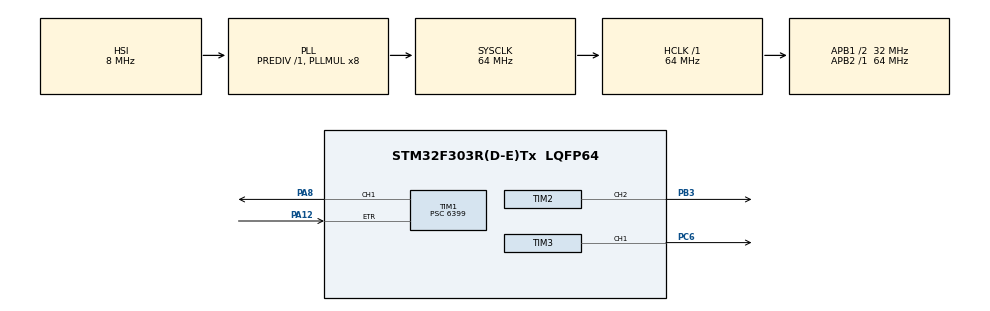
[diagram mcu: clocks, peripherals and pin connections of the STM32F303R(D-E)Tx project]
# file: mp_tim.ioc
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Mcu.Family=STM32F3
Mcu.Name=STM32F303R(D-E)Tx
Mcu.Package=LQFP64
NVIC.PriorityGroup=NVIC_PRIORITYGROUP_4
PA12.Signal=S_TIM1_ETR
PA13.Mode=Serial_Wire
PA13.Signal=SYS_JTMS-SWDIO
PA14.Mode=Serial_Wire
PA14.Signal=SYS_JTCK-SWCLK
PA8.Signal=S_TIM1_CH1
PB3.Signal=S_TIM2_CH2
PC6.Signal=S_TIM3_CH1
ProjectManager.HeapSize=0x200
ProjectManager.StackSize=0x400
ProjectManager.TargetToolchain=STM32CubeIDE
RCC.AHBFreq_Value=64000000
RCC.APB1CLKDivider=RCC_HCLK_DIV2
RCC.APB1Freq_Value=32000000
RCC.APB1TimFreq_Value=64000000
RCC.APB2Freq_Value=64000000
RCC.APB2TimFreq_Value=64000000
RCC.CortexFreq_Value=64000000
RCC.HCLKFreq_Value=64000000
RCC.HSE_VALUE=8000000
RCC.HSI_VALUE=8000000
RCC.LSE_VALUE=32768
RCC.PLLMUL=RCC_PLL_MUL8
RCC.SYSCLKFreq_VALUE=64000000
RCC.SYSCLKSourceVirtual=RCC_SYSCLKSOURCE_PLLCLK
RCC.USBFreq_Value=64000000
SH.S_TIM1_CH1.0=TIM1_CH1,PWM Generation1 CH1
SH.S_TIM1_ETR.0=TIM1_ETR,TriggerSource_ETR
SH.S_TIM2_CH2.0=TIM2_CH2,PWM Generation2 CH2
SH.S_TIM3_CH1.0=TIM3_CH1,PWM Generation1 CH1
TIM1.Channel-PWM\ Generation1\ CH1=TIM_CHANNEL_1
TIM1.OCMode_PWM-PWM\ Generation1\ CH1=TIM_OCMODE_PWM2
TIM1.Period=9999
TIM1.Prescaler=6399
TIM1.Pulse-PWM\ Generation1\ CH1=4999
TIM1.RepetitionCounter=2
TIM1.Slave_TriggerPolarity=TIM_TRIGGERPOLARITY_INVERTED
TIM1.TIM_MasterOutputTrigger=TIM_TRGO_UPDATE
TIM1.TIM_MasterSlaveMode=TIM_MASTERSLAVEMODE_ENABLE
TIM2.Channel-PWM\ Generation2\ CH2=TIM_CHANNEL_2
TIM2.OCMode_PWM-PWM\ Generation2\ CH2=TIM_OCMODE_PWM2
TIM2.Period=9999
TIM2.Prescaler=6399
TIM2.Pulse-PWM\ Generation2\ CH2=4999
TIM2.TIM_MasterOutputTrigger=TIM_TRGO_UPDATE
TIM2.TIM_MasterSlaveMode=TIM_MASTERSLAVEMODE_ENABLE
TIM3.Channel-PWM\ Generation1\ CH1=TIM_CHANNEL_1
TIM3.OCMode_PWM-PWM\ Generation1\ CH1=TIM_OCMODE_PWM2
TIM3.Period=9999
TIM3.Prescaler=6399
TIM3.Pulse-PWM\ Generation1\ CH1=4999
VP_TIM1_VS_ClockSourceINT.Mode=Internal
VP_TIM1_VS_ControllerModeTrigger.Mode=Trigger Mode
VP_TIM1_VS_OPM.Mode=OPM_bit
VP_TIM2_VS_ClockSourceINT.Mode=Internal
VP_TIM2_VS_ClockSourceITR.Mode=TriggerSource_ITR0
VP_TIM2_VS_ControllerModeTrigger.Mode=Trigger Mode
VP_TIM2_VS_OPM.Mode=OPM_bit
VP_TIM3_VS_ClockSourceINT.Mode=Internal
VP_TIM3_VS_ClockSourceITR.Mode=TriggerSource_ITR1
VP_TIM3_VS_ControllerModeTrigger.Mode=Trigger Mode
VP_TIM3_VS_OPM.Mode=OPM_bit
board=custom

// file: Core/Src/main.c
/* USER CODE BEGIN Header */
/**
  ******************************************************************************
  * @file           : main.c
  * @brief          : Main program body
  ******************************************************************************
  * @attention
  *
  * <h2><center>&copy; Copyright (c) 2021 STMicroelectronics.
  * All rights reserved.</center></h2>
  *
  * This software component is licensed by ST under BSD 3-Clause license,
  * the "License"; You may not use this file except in compliance with the
  * License. You may obtain a copy of the License at:
  *                        opensource.org/licenses/BSD-3-Clause
  *
  ******************************************************************************
  */
/* USER CODE END Header */

#include "main.h"

TIM_HandleTypeDef htim1;
TIM_HandleTypeDef htim2;
TIM_HandleTypeDef htim3;

void SystemClock_Config(void);
static void MX_GPIO_Init(void);
static void MX_TIM1_Init(void);
static void MX_TIM2_Init(void);
static void MX_TIM3_Init(void);

int main(void)
{

  /* MCU Configuration--------------------------------------------------------*/

  /* Reset of all peripherals, Initializes the Flash interface and the Systick. */
  HAL_Init();

  /* Configure the system clock */
  SystemClock_Config();

  /* Initialize all configured peripherals */
  MX_GPIO_Init();
  MX_TIM1_Init();
  MX_TIM2_Init();
  MX_TIM3_Init();
  /* USER CODE BEGIN 2 */
  HAL_TIM_OnePulse_Start(&htim1, TIM_CHANNEL_1);
  HAL_TIM_OnePulse_Start(&htim2, TIM_CHANNEL_2);
  HAL_TIM_OnePulse_Start(&htim3, TIM_CHANNEL_1);
  /* USER CODE END 2 */

  /* Infinite loop */
  while (1)
  {

  }
}

void SystemClock_Config(void)
{
  RCC_OscInitTypeDef RCC_OscInitStruct = {0};
  RCC_ClkInitTypeDef RCC_ClkInitStruct = {0};
  RCC_PeriphCLKInitTypeDef PeriphClkInit = {0};

  /** Initializes the CPU, AHB and APB busses clocks
  */
  RCC_OscInitStruct.OscillatorType = RCC_OSCILLATORTYPE_HSI;
  RCC_OscInitStruct.HSIState = RCC_HSI_ON;
  RCC_OscInitStruct.HSICalibrationValue = RCC_HSICALIBRATION_DEFAULT;
  RCC_OscInitStruct.PLL.PLLState = RCC_PLL_ON;
  RCC_OscInitStruct.PLL.PLLSource = RCC_PLLSOURCE_HSI;
  RCC_OscInitStruct.PLL.PLLMUL = RCC_PLL_MUL8;
  RCC_OscInitStruct.PLL.PREDIV = RCC_PREDIV_DIV1;
  if (HAL_RCC_OscConfig(&RCC_OscInitStruct) != HAL_OK)
  {
    Error_Handler();
  }
  /** Initializes the CPU, AHB and APB busses clocks
  */
  RCC_ClkInitStruct.ClockType = RCC_CLOCKTYPE_HCLK|RCC_CLOCKTYPE_SYSCLK
                              |RCC_CLOCKTYPE_PCLK1|RCC_CLOCKTYPE_PCLK2;
  RCC_ClkInitStruct.SYSCLKSource = RCC_SYSCLKSOURCE_PLLCLK;
  RCC_ClkInitStruct.AHBCLKDivider = RCC_SYSCLK_DIV1;
  RCC_ClkInitStruct.APB1CLKDivider = RCC_HCLK_DIV2;
  RCC_ClkInitStruct.APB2CLKDivider = RCC_HCLK_DIV1;

  if (HAL_RCC_ClockConfig(&RCC_ClkInitStruct, FLASH_LATENCY_2) != HAL_OK)
  {
    Error_Handler();
  }
  PeriphClkInit.PeriphClockSelection = RCC_PERIPHCLK_TIM1|RCC_PERIPHCLK_TIM2
                              |RCC_PERIPHCLK_TIM34;
  PeriphClkInit.Tim1ClockSelection = RCC_TIM1CLK_HCLK;
  PeriphClkInit.Tim2ClockSelection = RCC_TIM2CLK_HCLK;
  PeriphClkInit.Tim34ClockSelection = RCC_TIM34CLK_HCLK;
  if (HAL_RCCEx_PeriphCLKConfig(&PeriphClkInit) != HAL_OK)
  {
    Error_Handler();
  }
}

static void MX_TIM1_Init(void)
{

  TIM_ClockConfigTypeDef sClockSourceConfig = {0};
  TIM_SlaveConfigTypeDef sSlaveConfig = {0};
  TIM_MasterConfigTypeDef sMasterConfig = {0};
  TIM_OC_InitTypeDef sConfigOC = {0};
  TIM_BreakDeadTimeConfigTypeDef sBreakDeadTimeConfig = {0};

  htim1.Instance = TIM1;
  htim1.Init.Prescaler = 6399;
  htim1.Init.CounterMode = TIM_COUNTERMODE_UP;
  htim1.Init.Period = 9999;
  htim1.Init.ClockDivision = TIM_CLOCKDIVISION_DIV1;
  htim1.Init.RepetitionCounter = 2;
  htim1.Init.AutoReloadPreload = TIM_AUTORELOAD_PRELOAD_DISABLE;
  if (HAL_TIM_Base_Init(&htim1) != HAL_OK)
  {
    Error_Handler();
  }
  sClockSourceConfig.ClockSource = TIM_CLOCKSOURCE_INTERNAL;
  if (HAL_TIM_ConfigClockSource(&htim1, &sClockSourceConfig) != HAL_OK)
  {
    Error_Handler();
  }
  if (HAL_TIM_PWM_Init(&htim1) != HAL_OK)
  {
    Error_Handler();
  }
  if (HAL_TIM_OnePulse_Init(&htim1, TIM_OPMODE_SINGLE) != HAL_OK)
  {
    Error_Handler();
  }
  sSlaveConfig.SlaveMode = TIM_SLAVEMODE_TRIGGER;
  sSlaveConfig.InputTrigger = TIM_TS_ETRF;
  sSlaveConfig.TriggerPolarity = TIM_TRIGGERPOLARITY_INVERTED;
  sSlaveConfig.TriggerPrescaler = TIM_TRIGGERPRESCALER_DIV1;
  sSlaveConfig.TriggerFilter = 0;
  if (HAL_TIM_SlaveConfigSynchro(&htim1, &sSlaveConfig) != HAL_OK)
  {
    Error_Handler();
  }
  sMasterConfig.MasterOutputTrigger = TIM_TRGO_UPDATE;
  sMasterConfig.MasterOutputTrigger2 = TIM_TRGO2_RESET;
  sMasterConfig.MasterSlaveMode = TIM_MASTERSLAVEMODE_ENABLE;
  if (HAL_TIMEx_MasterConfigSynchronization(&htim1, &sMasterConfig) != HAL_OK)
  {
    Error_Handler();
  }
  sConfigOC.OCMode = TIM_OCMODE_PWM2;
  sConfigOC.Pulse = 4999;
  sConfigOC.OCPolarity = TIM_OCPOLARITY_HIGH;
  sConfigOC.OCNPolarity = TIM_OCNPOLARITY_HIGH;
  sConfigOC.OCFastMode = TIM_OCFAST_DISABLE;
  sConfigOC.OCIdleState = TIM_OCIDLESTATE_RESET;
  sConfigOC.OCNIdleState = TIM_OCNIDLESTATE_RESET;
  if (HAL_TIM_PWM_ConfigChannel(&htim1, &sConfigOC, TIM_CHANNEL_1) != HAL_OK)
  {
    Error_Handler();
  }
  sBreakDeadTimeConfig.OffStateRunMode = TIM_OSSR_DISABLE;
  sBreakDeadTimeConfig.OffStateIDLEMode = TIM_OSSI_DISABLE;
  sBreakDeadTimeConfig.LockLevel = TIM_LOCKLEVEL_OFF;
  sBreakDeadTimeConfig.DeadTime = 0;
  sBreakDeadTimeConfig.BreakState = TIM_BREAK_DISABLE;
  sBreakDeadTimeConfig.BreakPolarity = TIM_BREAKPOLARITY_HIGH;
  sBreakDeadTimeConfig.BreakFilter = 0;
  sBreakDeadTimeConfig.Break2State = TIM_BREAK2_DISABLE;
  sBreakDeadTimeConfig.Break2Polarity = TIM_BREAK2POLARITY_HIGH;
  sBreakDeadTimeConfig.Break2Filter = 0;
  sBreakDeadTimeConfig.AutomaticOutput = TIM_AUTOMATICOUTPUT_DISABLE;
  if (HAL_TIMEx_ConfigBreakDeadTime(&htim1, &sBreakDeadTimeConfig) != HAL_OK)
  {
    Error_Handler();
  }
  HAL_TIM_MspPostInit(&htim1);

}

static void MX_TIM2_Init(void)
{

  TIM_ClockConfigTypeDef sClockSourceConfig = {0};
  TIM_SlaveConfigTypeDef sSlaveConfig = {0};
  TIM_MasterConfigTypeDef sMasterConfig = {0};
  TIM_OC_InitTypeDef sConfigOC = {0};

  htim2.Instance = TIM2;
  htim2.Init.Prescaler = 6399;
  htim2.Init.CounterMode = TIM_COUNTERMODE_UP;
  htim2.Init.Period = 9999;
  htim2.Init.ClockDivision = TIM_CLOCKDIVISION_DIV1;
  htim2.Init.AutoReloadPreload = TIM_AUTORELOAD_PRELOAD_DISABLE;
  if (HAL_TIM_Base_Init(&htim2) != HAL_OK)
  {
    Error_Handler();
  }
  sClockSourceConfig.ClockSource = TIM_CLOCKSOURCE_INTERNAL;
  if (HAL_TIM_ConfigClockSource(&htim2, &sClockSourceConfig) != HAL_OK)
  {
    Error_Handler();
  }
  if (HAL_TIM_PWM_Init(&htim2) != HAL_OK)
  {
    Error_Handler();
  }
  if (HAL_TIM_OnePulse_Init(&htim2, TIM_OPMODE_SINGLE) != HAL_OK)
  {
    Error_Handler();
  }
  sSlaveConfig.SlaveMode = TIM_SLAVEMODE_TRIGGER;
  sSlaveConfig.InputTrigger = TIM_TS_ITR0;
  if (HAL_TIM_SlaveConfigSynchro(&htim2, &sSlaveConfig) != HAL_OK)
  {
    Error_Handler();
  }
  sMasterConfig.MasterOutputTrigger = TIM_TRGO_UPDATE;
  sMasterConfig.MasterSlaveMode = TIM_MASTERSLAVEMODE_ENABLE;
  if (HAL_TIMEx_MasterConfigSynchronization(&htim2, &sMasterConfig) != HAL_OK)
  {
    Error_Handler();
  }
  sConfigOC.OCMode = TIM_OCMODE_PWM2;
  sConfigOC.Pulse = 4999;
  sConfigOC.OCPolarity = TIM_OCPOLARITY_HIGH;
  sConfigOC.OCFastMode = TIM_OCFAST_DISABLE;
  if (HAL_TIM_PWM_ConfigChannel(&htim2, &sConfigOC, TIM_CHANNEL_2) != HAL_OK)
  {
    Error_Handler();
  }
  HAL_TIM_MspPostInit(&htim2);

}

static void MX_TIM3_Init(void)
{

  TIM_ClockConfigTypeDef sClockSourceConfig = {0};
  TIM_SlaveConfigTypeDef sSlaveConfig = {0};
  TIM_MasterConfigTypeDef sMasterConfig = {0};
  TIM_OC_InitTypeDef sConfigOC = {0};

  htim3.Instance = TIM3;
  htim3.Init.Prescaler = 6399;
  htim3.Init.CounterMode = TIM_COUNTERMODE_UP;
  htim3.Init.Period = 9999;
  htim3.Init.ClockDivision = TIM_CLOCKDIVISION_DIV1;
  htim3.Init.AutoReloadPreload = TIM_AUTORELOAD_PRELOAD_DISABLE;
  if (HAL_TIM_Base_Init(&htim3) != HAL_OK)
  {
    Error_Handler();
  }
  sClockSourceConfig.ClockSource = TIM_CLOCKSOURCE_INTERNAL;
  if (HAL_TIM_ConfigClockSource(&htim3, &sClockSourceConfig) != HAL_OK)
  {
    Error_Handler();
  }
  if (HAL_TIM_PWM_Init(&htim3) != HAL_OK)
  {
    Error_Handler();
  }
  if (HAL_TIM_OnePulse_Init(&htim3, TIM_OPMODE_SINGLE) != HAL_OK)
  {
    Error_Handler();
  }
  sSlaveConfig.SlaveMode = TIM_SLAVEMODE_TRIGGER;
  sSlaveConfig.InputTrigger = TIM_TS_ITR1;
  if (HAL_TIM_SlaveConfigSynchro(&htim3, &sSlaveConfig) != HAL_OK)
  {
    Error_Handler();
  }
  sMasterConfig.MasterOutputTrigger = TIM_TRGO_RESET;
  sMasterConfig.MasterSlaveMode = TIM_MASTERSLAVEMODE_DISABLE;
  if (HAL_TIMEx_MasterConfigSynchronization(&htim3, &sMasterConfig) != HAL_OK)
  {
    Error_Handler();
  }
  sConfigOC.OCMode = TIM_OCMODE_PWM2;
  sConfigOC.Pulse = 4999;
  sConfigOC.OCPolarity = TIM_OCPOLARITY_HIGH;
  sConfigOC.OCFastMode = TIM_OCFAST_DISABLE;
  if (HAL_TIM_PWM_ConfigChannel(&htim3, &sConfigOC, TIM_CHANNEL_1) != HAL_OK)
  {
    Error_Handler();
  }
  HAL_TIM_MspPostInit(&htim3);

}

static void MX_GPIO_Init(void)
{

  /* GPIO Ports Clock Enable */
  __HAL_RCC_GPIOC_CLK_ENABLE();
  __HAL_RCC_GPIOA_CLK_ENABLE();
  __HAL_RCC_GPIOB_CLK_ENABLE();

}

void Error_Handler(void)
{
}

/************************ (C) COPYRIGHT STMicroelectronics *****END OF FILE****/
